# RN821X_RN721X_SOC_V2 register map
File version: v1.0.7
CPU: CM0 r0p0, little endian, no MPU, no FPU, 3 interrupt priority bits
Registers are 32-bit, read-write, reset 0x0 unless marked. A register's access mark holds for its fields unless they carry their own. Offsets are from the block's base; [hi:lo] are bit positions; {n}, {i} and the like mark numbered series.

## RTC — real time clock
Base 0x4003C000
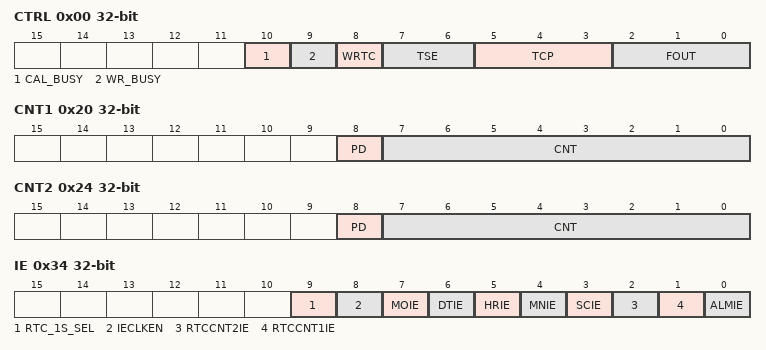
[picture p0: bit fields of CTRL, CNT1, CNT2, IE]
0x00 CTRL — control register
  [10] CAL_BUSY ro — RTC calibration busy flag
  [9] WR_BUSY ro — RTC register writing busy flag (RTC register only can be changed or set when Wr_busy is 0)
  [8] WRTC — RTC register write enable/disable bit
    0=DIS (RTC register set as read_only); 1=EN (RTC register set as writable)
  [7:6] TSE — temperature sensor enable configuration bits
    0=DIS (disable automatic temperature compensation); 1=AUTOEN (enable automatic cyclic temperature compensation); 2=USER0EN (enable user mode 0, automatic temperature compensation triggered by setting temperature(temperature set by user)); 3=USER1EN (enable user mode 1, automatic temperature compensation triggered by setting temperature(temperature unchangeable))
  [5:3] TCP — temperature compensation period bits
    0=2S (select temperature compensation period as 2 second); 1=10S (select temperature compensation period as 10 second); 2=20S (select temperature compensation period as 20 second); 3=30S (select temperature compensation period as 30 second); 4=1MIN (select temperature compensation period as 1 minute); 5=2MIN (select temperature compensation period as 2 minute); 6=5MIN (select temperature compensation period as 5 minute); 7=10MIN (select temperature compensation period as 10 minute)
  [2:0] FOUT — output frequency selections bits
    0=NUL (output forbidden); 1=1HZ (output PLL_1Hz when PLL_MODE=1,output LOSC_1Hz when PLL_MODE=0); 2=1_30HZ (select output frequency of 1/30Hz); 3=32KHZ (select output frequency of 32768Hz); 4=16HZ (select output frequency of 16Hz); 5=8HZ (select output frequency of 8Hz); 6=4HZ (select output frequency of 4Hz)
0x04 SC — seconds register
  [6:0] SC — seconds bits (BCD format, SC[6:4] standing for 10 seconds,SC[3:0] standing seconds)
0x08 MN — minutes register
  [6:0] MN — minutes bits (BCD format, MN[6:4] standing for 10 minutes,MN[3:0] standing for minutes)
0x0C HR — hours register
  [5:0] HR — hours bits (BCD format, HR[5:4] standing for 10 hours,HR[3:0] standing for hours)
0x10 DT — date register
  [5:0] DT — date bits (BCD format, DT[5:4] standing for 10 date,DT[3:0] standing for date)
0x14 MO — month register
  [4:0] MO — month bits (BCD format, MO[5] standing for 10 month,MO[3:0] standing for month)
0x18 YR — year register
  [7:0] YR — year bits (BCD format, YR[7:4] standing for 10 year,YR[3:0] standing for year)
0x1C DW — day of the week register
  [2:0] DW — day of the week bits
0x20 CNT1 — RTC counter1 register
  [8] PD — RTC CNT1 ON/OFF control bit
    0=ON (counter1 on (from perpetual calendar second interrupt)); 1=OFF (counter1 off, reset the counter value and restart)
  [7:0] CNT — RTC counter1 perset value bits(set CNT1 flag every (CNT+1) seconds)
0x24 CNT2 — RTC counter2 register
  [8] PD — RTC CNT2 ON/OFF control bit
    0=ON (counter2 on(from internal 1/256 s interrupt)); 1=OFF (counter2 off, reset the counter value)
  [7:0] CNT — RTC counter2 perset value bits(set counter2 flag every (CNT+1)/256 seconds)
0x28 SCA — alarm seconds register
  [6:0] SCA — alarm seconds bits (BCD format,SCA[6:4] standing for 10 seconds,SCA[3:0] standing for seconds)
0x2C MNA — alarm minitues register
  [6:0] MNA — alarm minitues bits (BCD format,MNA[6:4] standing for 10 minitues,MNA[3:0] standing for minitues)
0x30 HRA — alarm hours register
  [5:0] HRA — alarm hours bits (BCD format,MNA[5:4] standing for 10 hours,MNA[3:0] standing for hours)
0x34 IE — interrupt enable register
  [all] fields
    0=DIS (enable); 1=EN (disable)
  [9] RTC_1S_SEL — RTC_1S clock source selection bit
  [8] IECLKEN — interrupt clock enable bit.enabled when any bit of RTC_IE[8:0] is high
  [7] MOIE — month interrupt enable bit
  [6] DTIE — date interrupt enable bit
  [5] HRIE — hour interrupt enable bit
  [4] MNIE — minute interrupt enable bit
  [3] SCIE — sencond interrupt enable bit
  [2] RTCCNT2IE — counter2 interrupt enable bit
  [1] RTCCNT1IE — counter1 interrupt enable bit
  [0] ALMIE — alarm interrupt enable bit
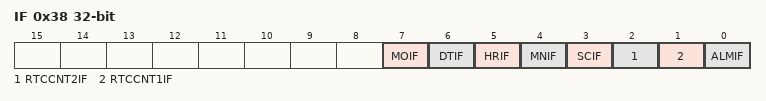
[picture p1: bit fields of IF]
0x38 IF — RTC interrupt flags register
  [all] fields
    0=NUL (no outstanding alarm event occurred); 1=OCC (event accured)
  [7] MOIF write-1-clears — month event interrupt flag
  [6] DTIF write-1-clears — date event interrupt flag
  [5] HRIF write-1-clears — hour event interrupt flag
  [4] MNIF write-1-clears — minute event interrupt flag
  [3] SCIF write-1-clears — sencond event interrupt flag
  [2] RTCCNT2IF write-1-clears — counter2 event interrupt flag
  [1] RTCCNT1IF write-1-clears — counter1 event interrupt flag
  [0] ALMIF write-1-clears — alarm event interrupt flag
0x3C TEMP — current chip temperature register No.1
  [9:0] TEMP — current chip temperature bits(TEMP[9] for sign, TEMP[8:2] for integer part,TEMP[1:0] for decimal part)
0x40 PS — RTC compensation registers password config register
  [7:0] PS — password config bits
0x44 MODE — RTC compensation mode config register
  [0] MODE — compensation mode config bits
0x48 DOTA0 — initial freq deviation register
  [12:0] DOTA0 — initial freq deviation bits
0x4C ALPHAL — RTC low temperature coefficient ALPHA config register
  [10:0] ALPHAL — RTC low temperature coefficient ALPHA config bits
0x50 ALPHAH — RTC high temperature coefficient ALPHA config register
  [10:0] ALPHAH — RTC high temperature coefficient ALPHA config bits
0x54 XT0 — RTC temperature curve vertex temperature XT0 register
  [6:0] XT0 — RTC temperature curve vertex temperature bits
0x58 TADJ — RTC prodution single point correction register
  [10:0] TADJ — RTC prodution single point correctionbits
0x60 ZT — RTC coefficient config register ZT
  [14:0] ZT — coefficient config register ZT bits
0x64 DOTAT — RTC total compensation register
  [15:0] DOTAT — total compensation bits
0x74 FPTR — RTC PLL compensation register
  [15:0] FPTR — PLL compensation bits
0x78 FDTR1S — RTC compensation register(per 1 seconds)
  [5:0] FDTR1S — RTC compensation bits
0x7C FDTR30S — RTC compensation register(per 30 seconds)
  [6:0] FDTR30S — RTC compensation bits
0x84 FDTR120S — RTC compensation register(per 120 seconds)
  [8:0] FDTR120S — RTC compensation bits
0xC4 TEMPOS — nomal mode temperature offset register
  [5:0] TEMPOS — nomal mode temperature offset bits
0xCC CALPS — Password register for RTC calibration registers
  [7:0] CALPS — Password bits for RTC secondary calibration registers
    168=ENABLE (enable write of RTC secondary calibration registers); 0=DISABLE (RTC secondary calibration registers write disable)
0xD0 CAL_T0 — RTC calibration register T0
  [7:0] CAL_T0 — RTC calibration register T0 bits (to calibrate RTC for 0.25ppm per bit when temprature is lower than -30 degree)
0xD4 CAL_T1 — RTC calibration register T1
  [7:0] CAL_T1 — RTC calibration register T1 bits (to calibrate RTC for 0.25ppm per bit when temprature is between -30 and -20 degree)
0xD8 CAL_T2 — RTC calibration register T2
  [7:0] CAL_T2 — RTC calibration register T2 bits (to calibrate RTC for 0.25ppm per bit when temprature is between -20 and -10 degree)
0xDC CAL_T3 — RTC calibration register T3
  [7:0] CAL_T3 — RTC calibration register T3 bits (to calibrate RTC for 0.25ppm per bit when temprature is between -10 and 0 degree)
0xE0 CAL_T4 — RTC calibration register T4
  [7:0] CAL_T4 — RTC calibration register T4 bits (to calibrate RTC for 0.25ppm per bit when temprature is between 0 and 10 degree)
{0xD0+4i} CAL_T{i} (i=5..8) — RTC calibration register T{i}
  [7:0] CAL_T{i} — RTC calibration register T{i} bits (to calibrate RTC for 0.25ppm per bit when temprature is between {10i-15} and {10i-5} degree)
0xF4 CAL_T9 — RTC calibration register T9
  [7:0] CAL_T9 — RTC calibration register T9 bits (to calibrate RTC for 0.25ppm per bit when temprature is higher than 75 degree)
0xF8 TEMP2 — current chip temperature register No.2
  [11:0] TEMP2 — current chip temperature bits(TEMP[11] for sign, TEMP[10:4] for integer part,TEMP[3:0] for decimal part)
0x130 MODE1 — temperature compensation mode seletion register No.1
  [15:0] MODE1 — temperature compensation mode seletion bits
0x134 XT1 — RTC temperature curve vertex temperature XT1 register
  [12:0] XT1 — RTC temperature curve vertex temperature bits
0x138 ALPHA — temperature coefficient ALPHA config register
  [15:0] ALPHA — temperature coefficient ALPHA config bits
0x13C BETA — temperature coefficient BETA config register
  [14:0] BETA — temperature coefficient BETA config bits
0x140 GAMMA — temperature coefficient GAMMA config register
  [15:0] GAMMA — temperature coefficient GAMMA config bits
0x144 ZETA — temperature coefficient ZETA config register
  [15:0] ZETA — temperature coefficient ZETA config bits
0x150 TPS_START wo — RTC temperature measure start register
  [0] TPS_START — RTC temperature measure start bit
0x154 TEMP_CAL — RTC temperature register No.3
  [11:0] TEMP_CAL — RTC temperature register No.3 bits
0x188 TEMPOS2 — low power mode temperature offset register
  [5:0] TEMPOS2 — low power mode temperature offset bits
